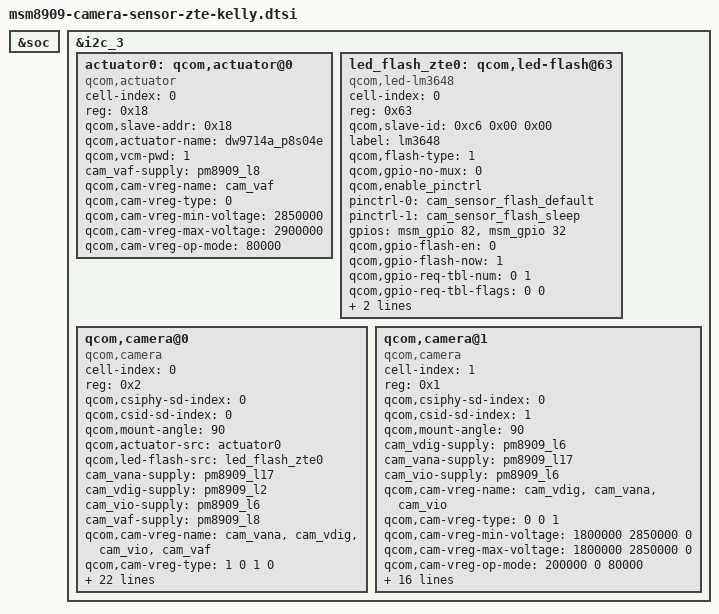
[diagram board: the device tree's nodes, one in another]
/*
 * Copyright (c) 2014-2015, The Linux Foundation. All rights reserved.
 *
 * This program is free software; you can redistribute it and/or modify
 * it under the terms of the GNU General Public License version 2 and
 * only version 2 as published by the Free Software Foundation.
 *
 * This program is distributed in the hope that it will be useful,
 * but WITHOUT ANY WARRANTY; without even the implied warranty of
 * MERCHANTABILITY or FITNESS FOR A PARTICULAR PURPOSE.  See the
 * GNU General Public License for more details.
 */

&soc {
};

&i2c_3 {
	actuator0: qcom,actuator@0 {
		cell-index = <0>;
		reg = <0x18>;
		qcom,slave-addr = <0x18>;
		compatible = "qcom,actuator";
		qcom,actuator-name = "dw9714a_p8s04e";
		qcom,vcm-pwd = <1>;
		/*qcom,cci-master = <0>; */
		cam_vaf-supply = <&pm8909_l8>;
		qcom,cam-vreg-name = "cam_vaf";
		qcom,cam-vreg-type = <0>;
		qcom,cam-vreg-min-voltage = <2850000>;
		qcom,cam-vreg-max-voltage = <2900000>;
		qcom,cam-vreg-op-mode = <80000>;
		status = "ok";
	};

 /* add zte sensor dtsi for led-flash*/
	led_flash_zte0: qcom,led-flash@63 {
		cell-index = <0>;
		reg = <0x63>;
		qcom,slave-id = <0xc6 0x00 0x00>;
		compatible = "qcom,led-lm3648";
		label = "lm3648";
		qcom,flash-type = <1>;
		qcom,gpio-no-mux = <0>;
		qcom,enable_pinctrl;
		pinctrl-names = "cam_flash_default", "cam_flash_suspend";
		pinctrl-0 = <&cam_sensor_flash_default>;
		pinctrl-1 = <&cam_sensor_flash_sleep>;
		gpios = <&msm_gpio 82 0>,
			<&msm_gpio 32 0>;
		qcom,gpio-flash-en = <0>;
		qcom,gpio-flash-now = <1>;
		qcom,gpio-req-tbl-num = <0 1>;
		qcom,gpio-req-tbl-flags = <0 0>;
		qcom,gpio-req-tbl-label = "FLASH_EN",
			"FLASH_NOW";
		qcom,cci-master = <0>;
		status = "ok";
	};

	qcom,camera@0 {
		cell-index = <0>;
		compatible = "qcom,camera";
		reg = <0x2>;
		qcom,csiphy-sd-index = <0>;
		qcom,csid-sd-index = <0>;
		qcom,mount-angle = <90>;
		qcom,actuator-src = <&actuator0>;
		qcom,led-flash-src = <&led_flash_zte0>;
		//qcom,eeprom-src = <&eeprom0>;
		cam_vana-supply = <&pm8909_l17>;
		cam_vdig-supply = <&pm8909_l2>;
		cam_vio-supply = <&pm8909_l6>;
		cam_vaf-supply = <&pm8909_l8>;
		qcom,cam-vreg-name = "cam_vana","cam_vdig", "cam_vio", "cam_vaf";
		qcom,cam-vreg-type = <1 0 1 0>;
		qcom,cam-vreg-min-voltage = <2800000 1200000 0 2850000>;
		qcom,cam-vreg-max-voltage = <2800000 1200000 0 2900000>;
		qcom,cam-vreg-op-mode = <2800000 200000 0 100000>;
		pinctrl-names = "cam_default", "cam_suspend";
		pinctrl-0 = <&cam_sensor_mclk0_default
				&cam_sensor_rear_default>;
		pinctrl-1 = <&cam_sensor_mclk0_sleep &cam_sensor_rear_sleep>;
		gpios = <&msm_gpio 26 0>,
			<&msm_gpio 35 0>,
			<&msm_gpio 34 0>,
			<&msm_gpio 99 0>;
		qcom,gpio-reset = <1>;
		qcom,gpio-standby = <2>;
		qcom,gpio-vana = <3>;
		qcom,gpio-req-tbl-num = <0 1 2 3>;
		qcom,gpio-req-tbl-flags = <1 0 0 0>;
		qcom,gpio-req-tbl-label = "CAMIF_MCLK",
			"CAM_RESET1",
			"CAM_STANDBY",
			"CAM_VANA";
		qcom,sensor-position = <0>;
		qcom,sensor-mode = <0>;
		/*qcom,cci-master = <0>;*/
		status = "ok";
		clocks = <&clock_gcc clk_mclk0_clk_src>,
				<&clock_gcc clk_gcc_camss_mclk0_clk>;
		clock-names = "cam_src_clk", "cam_clk";
	};

	qcom,camera@1 {
		cell-index = <1>;
		compatible = "qcom,camera";
		reg = <0x1>;
		qcom,csiphy-sd-index = <0>;
		qcom,csid-sd-index = <1>;
		qcom,mount-angle = <90>;
		cam_vdig-supply = <&pm8909_l6>;
		cam_vana-supply = <&pm8909_l17>;
		cam_vio-supply = <&pm8909_l6>;
		qcom,cam-vreg-name = "cam_vdig","cam_vana","cam_vio";
		qcom,cam-vreg-type = <0 0 1 >;
		qcom,cam-vreg-min-voltage = <1800000 2850000 0>;
		qcom,cam-vreg-max-voltage = <1800000 2850000 0>;
		qcom,cam-vreg-op-mode = <200000 0 80000>;
		pinctrl-names = "cam_default", "cam_suspend";
		pinctrl-0 = <&cam_sensor_mclk1_default &cam_sensor_front_default>;
		pinctrl-1 = <&cam_sensor_mclk1_sleep &cam_sensor_front_sleep>;
		gpios = <&msm_gpio 27 0>,
			<&msm_gpio 28 0>,
			<&msm_gpio 33 0>,
			<&msm_gpio 99 0>;
		qcom,gpio-reset = <1>;
		qcom,gpio-standby = <2>;
		qcom,gpio-vana = <3>;
		qcom,gpio-req-tbl-num = <0 1 2 3>;
		qcom,gpio-req-tbl-flags = <1 0 0 0>;
		qcom,gpio-req-tbl-label = "CAMIF_MCLK",
			"CAM_RESET",
			"CAM_STANDBY",
			"CAM_VANA";
		status = "ok";
		qcom,cci-master = <0>;
		clocks = <&clock_gcc clk_mclk1_clk_src>,
				<&clock_gcc clk_gcc_camss_mclk1_clk>;
		clock-names = "cam_src_clk", "cam_clk";
	};
};
